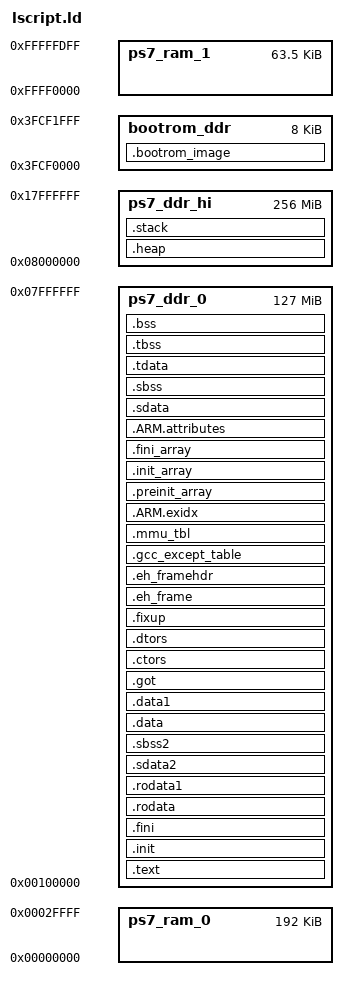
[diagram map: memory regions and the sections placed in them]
/*******************************************************************/
/*                                                                 */
/* This file is automatically generated by linker script generator.*/
/*                                                                 */
/* Version: 2018.3                                                 */
/*                                                                 */
/* Copyright (c) 2010-2016 Xilinx, Inc.  All rights reserved.      */
/*                                                                 */
/* Description : Cortex-A9 Linker Script                           */
/*                                                                 */
/*******************************************************************/

_STACK_SIZE = DEFINED(_STACK_SIZE) ? _STACK_SIZE : 0x4000;
_HEAP_SIZE = DEFINED(_HEAP_SIZE) ? _HEAP_SIZE : 0x08000000;

_ABORT_STACK_SIZE = DEFINED(_ABORT_STACK_SIZE) ? _ABORT_STACK_SIZE : 1024;
_SUPERVISOR_STACK_SIZE = DEFINED(_SUPERVISOR_STACK_SIZE) ? _SUPERVISOR_STACK_SIZE : 2048;
_IRQ_STACK_SIZE = DEFINED(_IRQ_STACK_SIZE) ? _IRQ_STACK_SIZE : 1024;
_FIQ_STACK_SIZE = DEFINED(_FIQ_STACK_SIZE) ? _FIQ_STACK_SIZE : 1024;
_UNDEF_STACK_SIZE = DEFINED(_UNDEF_STACK_SIZE) ? _UNDEF_STACK_SIZE : 1024;

/* Define Memories in the system */

MEMORY
{
   ps7_ddr_0 : ORIGIN = 0x100000, LENGTH = 0x07F00000
   ps7_ddr_hi : ORIGIN = 0x08000000, LENGTH = 0x10000000
   bootrom_ddr : ORIGIN = 0x3FCF0000, LENGTH = 0x2000
   ps7_ram_0 : ORIGIN = 0x0, LENGTH = 0x30000
   ps7_ram_1 : ORIGIN = 0xFFFF0000, LENGTH = 0xFE00
}

/* =======================================================================
 * XACP private-DDR linker guards.
 *
 * The linker must never place .heap, .stack, .bss or normal firmware
 * sections in the high DDR area reserved for XACP services. The symbols
 * below form conservative linker boundaries; the exact XACP v1.6 service
 * allocations are defined by the corresponding firmware service headers.
 *
 *   ps7_ddr_hi ends at 0x18000000
 *   conservative high-DDR guard starts at 0x20000000
 *   XACP allocations end before 0x30000000
 *   SMUSH codec storage starts at 0x30000000
 * ===================================================================== */
_XACP_POOL_BASE  = 0x20000000;
_XACP_POOL_SIZE  = 0x10000000;   /* 256 MB */
_XACP_POOL_END   = 0x30000000;
_XACP_DDR_HI_END = ORIGIN(ps7_ddr_hi) + LENGTH(ps7_ddr_hi);  /* 0x18000000 */
_XACP_SMUSH_BASE = 0x30000000;

/* =======================================================================
 * XX19c LOW-DDR framebuffer guard (verification only, no layout change).
 *
 * ps7_ddr_0 is ORIGIN 0x00100000, LENGTH 0x07F00000: it physically spans
 * THROUGH the ARM framebuffer at 0x00200000 up to 0x08000000. The linker
 * will therefore silently place low firmware sections (.text/.rodata/.data/
 * .bss) past 0x00200000 if the image grows. Such an overlap would corrupt
 * framebuffer memory and can cause display or system instability.
 *
 * These symbols + the ASSERTs at the end of SECTIONS make such an overlap a
 * hard LINK FAILURE. They allocate nothing and move no section.
 *
 *   _XACP_LOW_FB_BASE       mirrors FRAMEBUFFER_ADDRESS (memorymap.h)
 *   _XACP_LOW_FW_SAFE_LIMIT 64 KiB safety margin below the framebuffer
 * ===================================================================== */
_XACP_LOW_FB_BASE       = 0x00200000;
_XACP_LOW_FW_SAFE_LIMIT = 0x001F0000;


/* Specify the default entry point to the program */

ENTRY(_vector_table)

/* Define the sections, and where they are mapped in memory */

SECTIONS
{
.text : {
   KEEP (*(.vectors))
   *(.boot)
   *(.text)
   *(.text.*)
   *(.gnu.linkonce.t.*)
   *(.plt)
   *(.gnu_warning)
   *(.gcc_execpt_table)
   *(.glue_7)
   *(.glue_7t)
   *(.vfp11_veneer)
   *(.ARM.extab)
   *(.gnu.linkonce.armextab.*)
} > ps7_ddr_0

.init : {
   KEEP (*(.init))
} > ps7_ddr_0

.fini : {
   KEEP (*(.fini))
} > ps7_ddr_0

.rodata : {
   __rodata_start = .;
   *(.rodata)
   *(.rodata.*)
   *(.gnu.linkonce.r.*)
   __rodata_end = .;
} > ps7_ddr_0

.rodata1 : {
   __rodata1_start = .;
   *(.rodata1)
   *(.rodata1.*)
   __rodata1_end = .;
} > ps7_ddr_0

.sdata2 : {
   __sdata2_start = .;
   *(.sdata2)
   *(.sdata2.*)
   *(.gnu.linkonce.s2.*)
   __sdata2_end = .;
} > ps7_ddr_0

.sbss2 : {
   __sbss2_start = .;
   *(.sbss2)
   *(.sbss2.*)
   *(.gnu.linkonce.sb2.*)
   __sbss2_end = .;
} > ps7_ddr_0

.data : {
   __data_start = .;
   *(.data)
   *(.data.*)
   *(.gnu.linkonce.d.*)
   *(.jcr)
   *(.got)
   *(.got.plt)
   __data_end = .;
} > ps7_ddr_0

.data1 : {
   __data1_start = .;
   *(.data1)
   *(.data1.*)
   __data1_end = .;
} > ps7_ddr_0

.got : {
   *(.got)
} > ps7_ddr_0

.ctors : {
   __CTOR_LIST__ = .;
   ___CTORS_LIST___ = .;
   KEEP (*crtbegin.o(.ctors))
   KEEP (*(EXCLUDE_FILE(*crtend.o) .ctors))
   KEEP (*(SORT(.ctors.*)))
   KEEP (*(.ctors))
   __CTOR_END__ = .;
   ___CTORS_END___ = .;
} > ps7_ddr_0

.dtors : {
   __DTOR_LIST__ = .;
   ___DTORS_LIST___ = .;
   KEEP (*crtbegin.o(.dtors))
   KEEP (*(EXCLUDE_FILE(*crtend.o) .dtors))
   KEEP (*(SORT(.dtors.*)))
   KEEP (*(.dtors))
   __DTOR_END__ = .;
   ___DTORS_END___ = .;
} > ps7_ddr_0

.fixup : {
   __fixup_start = .;
   *(.fixup)
   __fixup_end = .;
} > ps7_ddr_0

.eh_frame : {
   *(.eh_frame)
} > ps7_ddr_0

.eh_framehdr : {
   __eh_framehdr_start = .;
   *(.eh_framehdr)
   __eh_framehdr_end = .;
} > ps7_ddr_0

.gcc_except_table : {
   *(.gcc_except_table)
} > ps7_ddr_0

.mmu_tbl (ALIGN(16384)) : {
   __mmu_tbl_start = .;
   *(.mmu_tbl)
   __mmu_tbl_end = .;
} > ps7_ddr_0

.ARM.exidx : {
   __exidx_start = .;
   *(.ARM.exidx*)
   *(.gnu.linkonce.armexidix.*.*)
   __exidx_end = .;
} > ps7_ddr_0

.preinit_array : {
   __preinit_array_start = .;
   KEEP (*(SORT(.preinit_array.*)))
   KEEP (*(.preinit_array))
   __preinit_array_end = .;
} > ps7_ddr_0

.init_array : {
   __init_array_start = .;
   KEEP (*(SORT(.init_array.*)))
   KEEP (*(.init_array))
   __init_array_end = .;
} > ps7_ddr_0

.fini_array : {
   __fini_array_start = .;
   KEEP (*(SORT(.fini_array.*)))
   KEEP (*(.fini_array))
   __fini_array_end = .;
} > ps7_ddr_0

.ARM.attributes : {
   __ARM.attributes_start = .;
   *(.ARM.attributes)
   __ARM.attributes_end = .;
} > ps7_ddr_0

.sdata : {
   __sdata_start = .;
   *(.sdata)
   *(.sdata.*)
   *(.gnu.linkonce.s.*)
   __sdata_end = .;
} > ps7_ddr_0

.sbss (NOLOAD) : {
   __sbss_start = .;
   *(.sbss)
   *(.sbss.*)
   *(.gnu.linkonce.sb.*)
   __sbss_end = .;
} > ps7_ddr_0

.tdata : {
   __tdata_start = .;
   *(.tdata)
   *(.tdata.*)
   *(.gnu.linkonce.td.*)
   __tdata_end = .;
} > ps7_ddr_0

.tbss : {
   __tbss_start = .;
   *(.tbss)
   *(.tbss.*)
   *(.gnu.linkonce.tb.*)
   __tbss_end = .;
} > ps7_ddr_0

.bss (NOLOAD) : {
   __bss_start = .;
   *(.bss)
   *(.bss.*)
   *(.gnu.linkonce.b.*)
   *(COMMON)
   __bss_end = .;
} > ps7_ddr_0

/* XX19c: end of the LOW firmware image (last section placed in ps7_ddr_0).
 * Captured here, BEFORE .heap/.stack switch the location counter to
 * ps7_ddr_hi. This is the value that must stay below the framebuffer. */
 __low_firmware_end = .;

_SDA_BASE_ = __sdata_start + ((__sbss_end - __sdata_start) / 2 );

_SDA2_BASE_ = __sdata2_start + ((__sbss2_end - __sdata2_start) / 2 );

/* Generate Stack and Heap definitions */

.heap (NOLOAD) : {
   . = ALIGN(16);
   _heap = .;
   HeapBase = .;
   _heap_start = .;
   . += _HEAP_SIZE;
   _heap_end = .;
   HeapLimit = .;
} > ps7_ddr_hi

.stack (NOLOAD) : {
   . = ALIGN(16);
   _stack_end = .;
   . += _STACK_SIZE;
   . = ALIGN(16);
   _stack = .;
   __stack = _stack;
   . = ALIGN(16);
   _irq_stack_end = .;
   . += _IRQ_STACK_SIZE;
   . = ALIGN(16);
   __irq_stack = .;
   _supervisor_stack_end = .;
   . += _SUPERVISOR_STACK_SIZE;
   . = ALIGN(16);
   __supervisor_stack = .;
   _abort_stack_end = .;
   . += _ABORT_STACK_SIZE;
   . = ALIGN(16);
   __abort_stack = .;
   _fiq_stack_end = .;
   . += _FIQ_STACK_SIZE;
   . = ALIGN(16);
   __fiq_stack = .;
   _undef_stack_end = .;
   . += _UNDEF_STACK_SIZE;
   . = ALIGN(16);
   __undef_stack = .;
} > ps7_ddr_hi

_end = .;

.bootrom_image : {
   KEEP(*(.bootrom_image))
} > bootrom_ddr
ASSERT(SIZEOF(.bootrom_image) == 0x2000, "bootrom_image must be exactly 8 KB")

/* =======================================================================
 * XACP high-DDR safety guards.
 *
 * Keep the firmware heap/stack region below the conservative XACP boundary
 * and keep XACP allocations below the SMUSH codec area.
 * ===================================================================== */
ASSERT(_XACP_DDR_HI_END <= _XACP_POOL_BASE,
       "FATAL: firmware heap/stack (ps7_ddr_hi) overlaps XACP private pool")
ASSERT(_XACP_POOL_END <= _XACP_SMUSH_BASE,
       "FATAL: XACP private pool overlaps SMUSH codec region 0x30000000")

/* =======================================================================
 * XX19c LOW-DDR framebuffer guards.
 *
 * (1) MANDATORY: the low firmware image must never reach the framebuffer.
 *     A future firmware too big to fit under 0x00200000 can no longer link.
 * (2) MARGIN: keep a 64 KiB cushion below the framebuffer so future
 *     firmware growth fails at link time before reaching framebuffer memory.
 * ===================================================================== */
ASSERT(__low_firmware_end <= _XACP_LOW_FB_BASE,
       "FATAL: low firmware image overlaps framebuffer at 0x00200000")
ASSERT(__low_firmware_end <= _XACP_LOW_FW_SAFE_LIMIT,
       "FATAL: low firmware image violates 64 KiB framebuffer safety margin")
}
